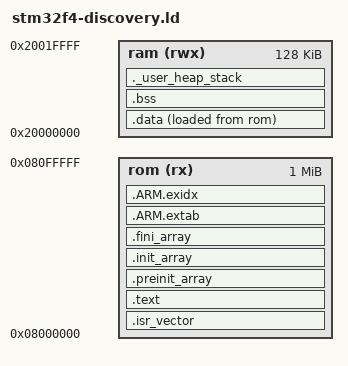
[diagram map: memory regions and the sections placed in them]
/*
 * This file is part of the libopencm3 project.
 *
 * Copyright (C) 2009 Uwe Hermann <uwe@hermann-uwe.de>
 *
 * This library is free software: you can redistribute it and/or modify
 * it under the terms of the GNU Lesser General Public License as published by
 * the Free Software Foundation, either version 3 of the License, or
 * (at your option) any later version.
 *
 * This library is distributed in the hope that it will be useful,
 * but WITHOUT ANY WARRANTY; without even the implied warranty of
 * MERCHANTABILITY or FITNESS FOR A PARTICULAR PURPOSE.  See the
 * GNU Lesser General Public License for more details.
 *
 * You should have received a copy of the GNU Lesser General Public License
 * along with this library.  If not, see <http://www.gnu.org/licenses/>.
 */

/* Generic linker script for STM32 targets using libopencm3. */

/* Memory regions must be defined in the ld script which includes this one. */

/* Enforce emmition of the vector table. */
EXTERN (vector_table)

/* Define the entry point of the output file. */
ENTRY(_start)

_estack = 0x20020000;    /* end of RAM */

/* Generate a link error if heap and stack don't fit into RAM */
_Min_Heap_Size = 0x200;
_Min_Stack_Size = 0x400;

MEMORY
{
	ram (rwx) : ORIGIN = 0x20000000, LENGTH = 128K
	rom (rx)  : ORIGIN = 0x08000000, LENGTH = 1024K
}

/* Define sections. */
SECTIONS
{
	/* Startup code */
	.isr_vector : {
		. = ALIGN(4);
		KEEP(*(.isr_vector)) 
		. = ALIGN(4);
	} >rom
	
	.text : {
		*(.vectors)
		*(.text*)	/* Program code */
		. = ALIGN(4);
		*(.rodata*)	/* Read-only data */
		. = ALIGN(4);
		*(.glue_7)         /* glue arm to thumb code */
                *(.glue_7t)        /* glue thumb to arm code */

		KEEP(*(.init))
		KEEP(*(.fini))

		. = ALIGN(4);
	} >rom

	/* C++ Static constructors/destructors, also used for __attribute__
	 * ((constructor)) and the likes */
	.preinit_array : {
		. = ALIGN(4);
		__preinit_array_start = .;
		KEEP (*(.preinit_array))
		__preinit_array_end = .;
	} >rom
	.init_array : {
		. = ALIGN(4);
		__init_array_start = .;
		KEEP (*(SORT(.init_array.*)))
		KEEP (*(.init_array))
		__init_array_end = .;
	} >rom
	.fini_array : {
		. = ALIGN(4);
		__fini_array_start = .;
		__libc_fini = .;
		KEEP (*(.fini_array))
		KEEP (*(SORT(.fini_array.*)))
		__fini_array_end = .;
	} >rom

	/*
	 * Another section used by C++ stuff, appears when using newlib with
	 * 64bit (long long) printf support
	 */
	.ARM.extab : {
		*(.ARM.extab*)
	} >rom
	.ARM.exidx : {
		__exidx_start = .;
		*(.ARM.exidx*)
		__exidx_end = .;
	} >rom

	. = ALIGN(4);
	_etext = .;

	.data : {
		_data = .;
		*(.data*)	/* Read-write initialized data */
		. = ALIGN(4);
		_edata = .;
	} >ram AT >rom
	_data_loadaddr = LOADADDR(.data);

	.bss : {
        __bss_start__ = .;
		*(.bss*)	/* Read-write zero initialized data */
		*(COMMON)
		. = ALIGN(4);
		_ebss = .;
        __bss_end__ = .;
	} >ram
	
	/* User_heap_stack section, used to check that there is enough RAM left */

	._user_heap_stack : 
	{
		. = ALIGN(8);
		PROVIDE ( end = . );
		PROVIDE ( _end = . );
		. = . + _Min_Heap_Size;
		. = . + _Min_Stack_Size;
		. = ALIGN(8);
	} >ram
	
	 
	/DISCARD/ :
  {
    libc.a ( * )
    libm.a ( * )
    libgcc.a ( * )
  }

	. = ALIGN(4);
	end = .;
}

PROVIDE(__stack = ORIGIN(ram) + LENGTH(ram));

